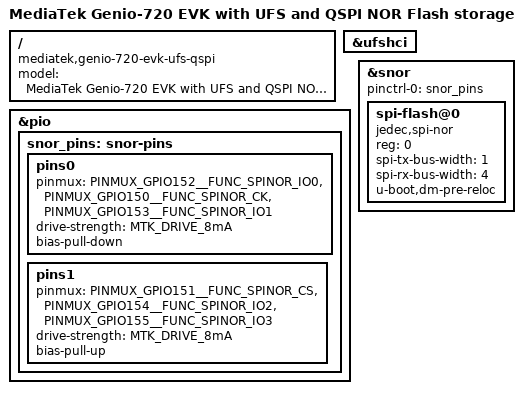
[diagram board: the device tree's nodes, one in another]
// SPDX-License-Identifier: GPL-2.0 OR MIT
/*
 * Copyright (C) 2025 MediaTek Inc.
 * Author: Macpaul Lin <macpaul.lin@mediatek.com>
 */

/dts-v1/;

#include "genio-720-evk-common.dtsi"

/ {
	model = "MediaTek Genio-720 EVK with UFS and QSPI NOR Flash storage";
	compatible = "mediatek,genio-720-evk-ufs-qspi", "mediatek,mt8391";
};

&ufshci {
	status = "okay";
};

&pio {
	snor_pins: snor-pins {
		pins0 {
			pinmux = <PINMUX_GPIO152__FUNC_SPINOR_IO0>,
				 <PINMUX_GPIO150__FUNC_SPINOR_CK>,
				 <PINMUX_GPIO153__FUNC_SPINOR_IO1>;
			drive-strength = <MTK_DRIVE_8mA>;
			bias-pull-down;
		};

		pins1 {
			pinmux = <PINMUX_GPIO151__FUNC_SPINOR_CS>,
				 <PINMUX_GPIO154__FUNC_SPINOR_IO2>,
				 <PINMUX_GPIO155__FUNC_SPINOR_IO3>;
			drive-strength = <MTK_DRIVE_8mA>;
			bias-pull-up;
		};
	};
};

&snor {
	pinctrl-names = "default";
	pinctrl-0 = <&snor_pins>;
	status = "okay";

	spi-flash@0 {
		compatible = "jedec,spi-nor";
		reg = <0>;
		spi-tx-bus-width = <1>;
		spi-rx-bus-width = <4>;
		u-boot,dm-pre-reloc;
	};
};
